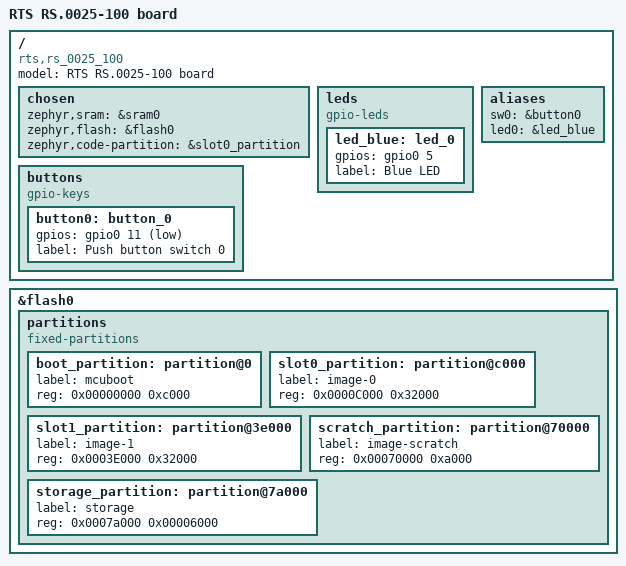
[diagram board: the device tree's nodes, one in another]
/*
 * Copyright (c) 2019 Stéphane D'Alu
 *
 * SPDX-License-Identifier: Apache-2.0
 */

/dts-v1/;
#include "decawave_dwm1001.dtsi"

/ {
    model = "RTS RS.0025-100 board";
    compatible = "rts,rs_0025_100";

	chosen {
        /*
		zephyr,console        = &uart0;
		zephyr,shell-uart     = &uart0;
		zephyr,uart-mcumgr    = &uart0;
		zephyr,bt-mon-uart    = &uart0;
		zephyr,bt-c2h-uart    = &uart0;
        */
		zephyr,sram           = &sram0;
		zephyr,flash          = &flash0;
		zephyr,code-partition = &slot0_partition;
	};

	leds {
		compatible = "gpio-leds";
		led_blue: led_0 {
			gpios = <&gpio0 5 GPIO_ACTIVE_HIGH>;
			label = "Blue LED";
		};
	};

	buttons {
		compatible = "gpio-keys";
		button0: button_0 {
			gpios = <&gpio0 11 (GPIO_PULL_UP | GPIO_ACTIVE_LOW)>;
			label = "Push button switch 0";
		};
	};

	aliases {
		sw0  = &button0;
		led0 = &led_blue;
	};

};

/*
&adc {
	status = "okay";
};

&uart0 {
	status = "okay";
	compatible = "nordic,nrf-uart";
	current-speed = <115200>;
	tx-pin  = <5>;
	rx-pin  = <11>;
};

&i2c0 {

};

&spi1 {
	compatible = "nordic,nrf-spi";
	status = "disabled";
	sck-pin  = <4>;
	mosi-pin = <6>;
	miso-pin = <7>;
	cs-gpios = <&gpio0 3 0>;
};

*/

&flash0 {

	partitions {
		compatible = "fixed-partitions";
		#address-cells = <1>;
		#size-cells = <1>;

		boot_partition: partition@0 {
			label = "mcuboot";
			reg = <0x00000000 0xc000>;
		};
		slot0_partition: partition@c000 {
			label = "image-0";
			reg = <0x0000C000 0x32000>;
		};
		slot1_partition: partition@3e000 {
			label = "image-1";
			reg = <0x0003E000 0x32000>;
		};
		scratch_partition: partition@70000 {
			label = "image-scratch";
			reg = <0x00070000 0xa000>;
		};
		storage_partition: partition@7a000 {
			label = "storage";
			reg = <0x0007a000 0x00006000>;
		};
	};
};
